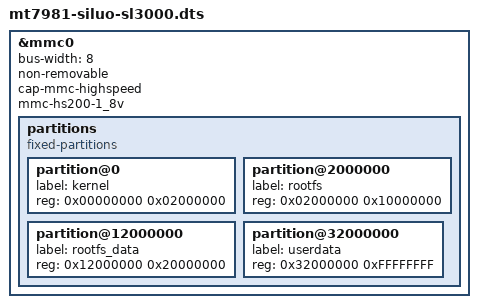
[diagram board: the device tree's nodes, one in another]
&mmc0 {
    status = "okay";
    bus-width = <8>;
    non-removable;
    cap-mmc-highspeed;
    mmc-hs200-1_8v;

    partitions {
        compatible = "fixed-partitions";
        #address-cells = <1>;
        #size-cells = <1>;

        /* 32MB kernel */
        partition@0 {
            label = "kernel";
            reg = <0x00000000 0x02000000>;
        };

        /* 256MB rootfs */
        partition@2000000 {
            label = "rootfs";
            reg = <0x02000000 0x10000000>;
        };

        /* rootfs_data 自动扩容 */
        partition@12000000 {
            label = "rootfs_data";
            reg = <0x12000000 0x20000000>; /* 512MB 预留，sysupgrade 后自动扩容 */
        };

        /* 剩余全部给 userdata（约 127GB） */
        partition@32000000 {
            label = "userdata";
            reg = <0x32000000 0xFFFFFFFF>; /* 自动到磁盘末尾 */
        };
    };
};
